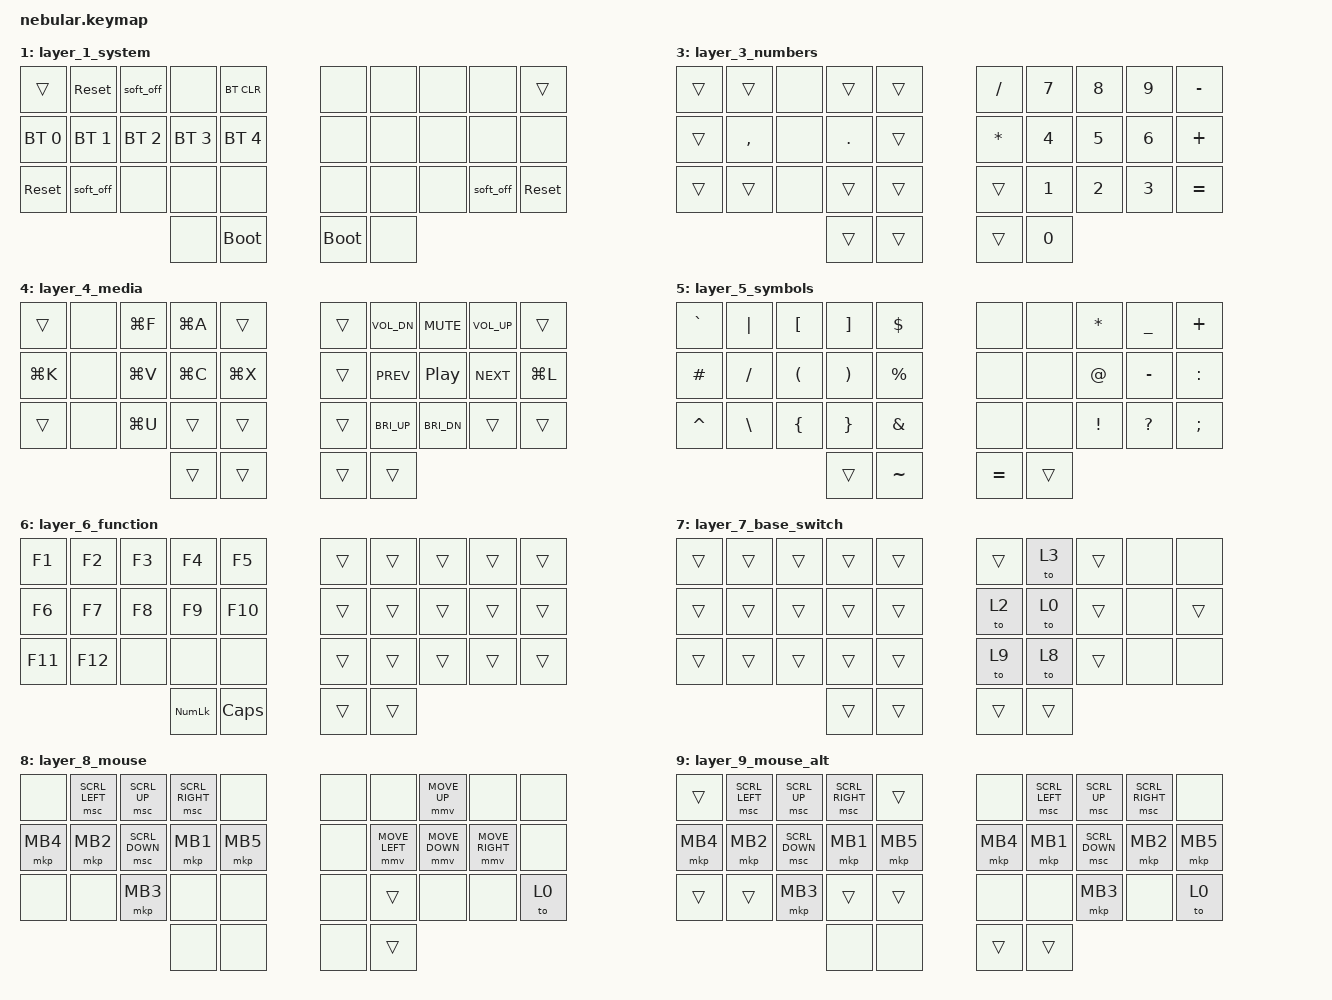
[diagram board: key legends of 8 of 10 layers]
// This file was generated from a template. Edit it to match your keyboard.
// See https://zmk.dev/docs/development/hardware-integration/new-shield for more instructions.
#define ZMK_POINTING_DEFAULT_MOVE_VAL 1500  // default: 600
#define ZMK_POINTING_DEFAULT_SCRL_VAL 20    // default: 10

#include <behaviors.dtsi>
#include <dt-bindings/zmk/keys.h>
#include <dt-bindings/zmk/reset.h>
#include <dt-bindings/zmk/bt.h>
#include <dt-bindings/zmk/outputs.h>
#include <dt-bindings/zmk/mouse.h>
#include <dt-bindings/zmk/pointing.h>


/ {
    behaviors {
        lt: layer_tap {
            compatible = "zmk,behavior-hold-tap";
            #binding-cells = <2>;
            tapping-term-ms = <170>; // tuned value
            quick-tap-ms = <0>;
            flavor = "tap-preferred";
            bindings = <&mo>, <&kp>;
        };

        mtc: mod_tap_custom {
            compatible = "zmk,behavior-hold-tap";
            #binding-cells = <2>;
            tapping-term-ms = <170>; // tuned value
            quick-tap-ms = <0>;
            flavor = "tap-preferred";
            bindings = <&kp>, <&kp>; // Placeholders
        };

        mts: mod_tap_shift_custom {
            compatible = "zmk,behavior-hold-tap";
            #binding-cells = <2>;
            tapping-term-ms = <170>; // tuned value
            quick-tap-ms = <0>;
            flavor = "tap-preferred";
            bindings = <&kp>, <&kp>; // Placeholders
        };
    };

    keymap {
        compatible = "zmk,keymap";

        /* ----- default_layer (Layer 0) -----
         * +---------+---------+---------+---------+---------+   +---------+---------+---------+---------+---------+
         * |  L1_Q   |  LC_W   |  LA_F   |    P    |    B    |   |    J    |  L5_L   |  RA_U   |  RC_Y   |  L1_'   |
         * +---------+---------+---------+---------+---------+   +---------+---------+---------+---------+---------+
         * |  LS_A   |  L4_R   |  L3_S   |  L2_T   |    G    |   |    M    |  L5_N   |  L6_E   |  L7_I   |  RS_O   |
         * +---------+---------+---------+---------+---------+   +---------+---------+---------+---------+---------+
         * |  HYP_Z  |    X    |    C    |    D    |    V    |   |    K    |    H    |    ,    |    .    |    ;    |
         * +---------+---------+---------+---------+---------+   +---------+---------+---------+---------+---------+
         *                               +---------+---------+   +---------+---------+
         *                               | LG_TAB  |   SPC   |   |  BSPC   |  RG_RET |
         *                               +---------+---------+   +---------+---------+
         *                                         +---------+
         *                                         | ENCODER |
         *                                         +---------+
         */
        default_layer {
            bindings = <
                &lt 1 Q                &mtc LCTRL W &mt LALT F    &kp P          &kp B        &kp J    &lt 5 L      &mt RALT U &mt RCTRL Y &lt 1 SQT
                &mts LSHFT A            &lt 4 R     &lt 3 S       &lt 2 T        &kp G        &kp M    &lt 5 N      &lt 6 E      &lt 7 I      &mts RSHFT O
                &mtc LC(LA(LS(LGUI))) Z &kp X       &kp C         &kp D          &kp V        &kp K    &kp H        &kp COMMA  &kp DOT     &kp SEMI
                                                    &mtc LGUI TAB &lt 9 SPACE    &kp BSPC     &mtc RGUI RET
                                                    &mkp LCLK
            >;
        };

        /* ----- layer_1_system (Layer 1) -----
         * +---------+---------+---------+---------+---------+   +---------+---------+---------+---------+---------+
         * |  TRNS   |  RESET  |  S_OFF  | _______ | BT_CLR  |   | _______ | _______ | _______ | _______ |  TRNS   |
         * +---------+---------+---------+---------+---------+   +---------+---------+---------+---------+---------+
         * |  BT_0   |  BT_1   |  BT_2   |  BT_3   |  BT_4   |   | _______ | _______ | _______ | _______ | _______ |
         * +---------+---------+---------+---------+---------+   +---------+---------+---------+---------+---------+
         * |  RESET  |  S_OFF  | _______ | _______ | _______ |   | _______ | _______ | _______ |  S_OFF  |  RESET  |
         * +---------+---------+---------+---------+---------+   +---------+---------+---------+---------+---------+
         *                               +---------+---------+   +---------+---------+
         *                               | _______ |  BOOT   |   |  BOOT   | _______ |
         *                               +---------+---------+   +---------+---------+
         */
        layer_1_system {
            bindings = <
                &trans       &sys_reset   &soft_off    &none        &bt BT_CLR    &none    &none    &none    &none     &trans
                &bt BT_SEL 0 &bt BT_SEL 1 &bt BT_SEL 2 &bt BT_SEL 3 &bt BT_SEL 4  &none    &none    &none    &none     &none
                &sys_reset   &soft_off    &none        &none        &none         &none    &none    &none    &soft_off &sys_reset
                                          &none       &bootloader                 &bootloader &none
            >;
        };

        /* ----- layer_2_navigation (Layer 2) -----
         * +---------+---------+---------+---------+---------+   +---------+---------+---------+---------+---------+
         * | _______ | _______ | _______ | _______ | _______ |   | _______ |  PGUP   |   UP    |  HOME   | _______ |
         * +---------+---------+---------+---------+---------+   +---------+---------+---------+---------+---------+
         * | _______ | _______ | _______ |  TRNS   | _______ |   |  CAPSW  |  LEFT   |  DOWN   |  RGHT   | _______ |
         * +---------+---------+---------+---------+---------+   +---------+---------+---------+---------+---------+
         * | _______ | _______ | _______ | _______ | _______ |   | _______ |  PGDN   |  LGSX   |   END   | _______ |
         * +---------+---------+---------+---------+---------+   +---------+---------+---------+---------+---------+
         *                               +---------+---------+   +---------+---------+
         *                               | _______ |   ESC   |   |   DEL   |  TRNS   |
         *                               +---------+---------+   +---------+---------+
         */
        layer_2_navigation {
            // Note: LGSX = LG(LS(X)) -> Cmd+Shift+X
            bindings = <
                &none       &none                  &none       &none      &none        &kp PG_DN         &kp PG_UP    &kp UP        &kp HOME     &kp END
                &none       &kp LC(LA(LS(LG(T))))  &kp LG(K)   &trans     &none        &kp LG(LS(LBKT))  &kp LEFT     &kp DOWN      &kp RIGHT    &kp LG(LS(RBKT))
                &none       &none                  &none       &none      &none        &caps_word        &kp LG(LBKT)) &kp LG(LS(X)) &kp LG(RBKT)) &none
                                                   &none       &kp ESC                 &kp DEL     &trans
            >;
        };

        /* ----- layer_3_numbers (Layer 3) -----
         * +---------+---------+---------+---------+---------+   +---------+---------+---------+---------+---------+
         * |  TRNS   |  TRNS   | _______ |  TRNS   |  TRNS   |   |    /    |   N7    |   N8    |   N9    |    -    |
         * +---------+---------+---------+---------+---------+   +---------+---------+---------+---------+---------+
         * |  TRNS   |    ,    | _______ |    .    |  TRNS   |   |    *    |   N4    |   N5    |   N6    |    +    |
         * +---------+---------+---------+---------+---------+   +---------+---------+---------+---------+---------+
         * |  TRNS   |  TRNS   | _______ |  TRNS   |  TRNS   |   |  TRNS   |   N1    |   N2    |   N3    |    =    |
         * +---------+---------+---------+---------+---------+   +---------+---------+---------+---------+---------+
         *                               +---------+---------+   +---------+---------+
         *                               |  TRNS   |  TRNS   |   |  TRNS   |   N0    |
         *                               +---------+---------+   +---------+---------+
         */
        layer_3_numbers {
            bindings = <
                &trans     &trans    &none     &trans    &trans       &kp SLASH  &kp N7     &kp N8    &kp N9    &kp MINUS
                &trans     &kp COMMA &none     &kp DOT   &trans       &kp STAR   &kp N4     &kp N5    &kp N6    &kp PLUS
                &trans     &trans    &none     &trans    &trans       &trans     &kp N1     &kp N2    &kp N3    &kp EQUAL
                                               &trans    &trans       &trans     &kp N0
            >;
        };

        /* ----- layer_4_media (Layer 4) -----
         * +---------+---------+---------+---------+---------+   +---------+---------+---------+---------+---------+
         * |  TRNS   | _______ |  FIND   |  SELA   |  TRNS   |   |  TRNS   |  VOL-   |  MUTE   |  VOL+   |  TRNS   |
         * +---------+---------+---------+---------+---------+   +---------+---------+---------+---------+---------+
         * |  LNK?   | _______ |  PASTE  |  COPY   |   CUT   |   |  TRNS   |  PREV   |  PLAY   |  NEXT   |   LOC   |
         * +---------+---------+---------+---------+---------+   +---------+---------+---------+---------+---------+
         * |  TRNS   | _______ |  SRCE?  |  TRNS   |  TRNS   |   |  TRNS   |  BRI+   |  BRI-   |  TRNS   |  TRNS   |
         * +---------+---------+---------+---------+---------+   +---------+---------+---------+---------+---------+
         *                               +---------+---------+   +---------+---------+
         *                               |  TRNS   |  TRNS   |   |  TRNS   |  TRNS   |
         *                               +---------+---------+   +---------+---------+
         */
        layer_4_media {
            // Note: FIND=LG(F), SELA=LG(A), LNK?=LG(K), PASTE=LG(V), COPY=LG(C),
            //       CUT=LG(X), SRCE?=LG(U), LOC=LG(L)
            bindings = <
                &trans      &none      &kp LG(F)  &kp LG(A)  &trans       &trans     &kp C_VOL_DN &kp C_MUTE &kp C_VOL_UP &trans
                &kp LG(K)   &none      &kp LG(V)  &kp LG(C)  &kp LG(X)    &trans     &kp C_PREV   &kp C_PP   &kp C_NEXT   &kp LG(L)
                &trans      &none      &kp LG(U)  &trans     &trans       &trans     &kp C_BRI_UP &kp C_BRI_DN &trans     &trans
                                                  &trans     &trans       &trans     &trans
            >;
        };

        /* ----- layer_5_symbols (Layer 5) -----
         * +---------+---------+---------+---------+---------+   +---------+---------+---------+---------+---------+
         * |    `    |    |    |    [    |    ]    |    $    |   | _______ | _______ |    *    |    _    |    +    |
         * +---------+---------+---------+---------+---------+   +---------+---------+---------+---------+---------+
         * |    #    |    /    |    (    |    )    |    %    |   | _______ | _______ |    @    |    -    |    :    |
         * +---------+---------+---------+---------+---------+   +---------+---------+---------+---------+---------+
         * |    ^    |    \    |    {    |    }    |    &    |   | _______ | _______ |    !    |    ?    |    ;    |
         * +---------+---------+---------+---------+---------+   +---------+---------+---------+---------+---------+
         *                               +---------+---------+   +---------+---------+
         *                               |  TRNS   |    ~    |   |    =    |  TRNS   |
         *                               +---------+---------+   +---------+---------+
         */
        layer_5_symbols {
            bindings = <
                &kp GRAVE   &kp PIPE   &kp LBKT   &kp RBKT   &kp DLLR      &none     &none      &kp ASTRK  &kp UNDER  &kp PLUS
                &kp HASH    &kp FSLH   &kp LPAR   &kp RPAR   &kp PRCNT     &none     &none      &kp AT     &kp MINUS  &kp COLON
                &kp CARET   &kp BSLH   &kp LBRC   &kp RBRC   &kp AMPS      &none     &none      &kp EXCL   &kp QMARK  &kp SEMI
                                                  &trans     &kp TILDE     &kp EQUAL &trans
            >;
        };

        /* ----- layer_6_function (Layer 6) -----
         * +---------+---------+---------+---------+---------+   +---------+---------+---------+---------+---------+
         * |   F1    |   F2    |   F3    |   F4    |   F5    |   |  TRNS   |  TRNS   |  TRNS   |  TRNS   |  TRNS   |
         * +---------+---------+---------+---------+---------+   +---------+---------+---------+---------+---------+
         * |   F6    |   F7    |   F8    |   F9    |   F10   |   |  TRNS   |  TRNS   |  TRNS   |  TRNS   |  TRNS   |
         * +---------+---------+---------+---------+---------+   +---------+---------+---------+---------+---------+
         * |   F11   |   F12   | _______ | _______ | _______ |   |  TRNS   |  TRNS   |  TRNS   |  TRNS   |  TRNS   |
         * +---------+---------+---------+---------+---------+   +---------+---------+---------+---------+---------+
         *                               +---------+---------+   +---------+---------+
         *                               |   NUM   |  CAPS   |   |  TRNS   |  TRNS   |
         *                               +---------+---------+   +---------+---------+
         */
        layer_6_function {
             bindings = <
                &kp F1      &kp F2    &kp F3         &kp F4     &kp F5            &trans &trans &trans &trans &trans
                &kp F6      &kp F7    &kp F8         &kp F9     &kp F10           &trans &trans &trans &trans &trans
                &kp F11     &kp F12   &none          &none      &none             &trans &trans &trans &trans &trans
                                                     &kp KP_NUM &kp CAPS          &trans &trans
             >;
         };

        /* ----- layer_7_base_switch (Layer 7) -----
         * +---------+---------+---------+---------+---------+   +---------+---------+---------+---------+---------+
         * |  TRNS   |  TRNS   |  TRNS   |  TRNS   |  TRNS   |   |  TRNS   |  TO_3   |  TRNS   | _______ | _______ |
         * +---------+---------+---------+---------+---------+   +---------+---------+---------+---------+---------+
         * |  TRNS   |  TRNS   |  TRNS   |  TRNS   |  TRNS   |   |  TO_2   |  TO_0   |  TRNS   | _______ |  TRNS   |
         * +---------+---------+---------+---------+---------+   +---------+---------+---------+---------+---------+
         * |  TRNS   |  TRNS   |  TRNS   |  TRNS   |  TRNS   |   |  TO_9   |  TO_8   |  TRNS   | _______ | _______ |
         * +---------+---------+---------+---------+---------+   +---------+---------+---------+---------+---------+
         *                               +---------+---------+   +---------+---------+
         *                               |  TRNS   |  TRNS   |   |  TRNS   |  TRNS   |
         *                               +---------+---------+   +---------+---------+
         */
        layer_7_base_switch {
            // Note: TO_x switches the base layer permanently. TO_8/TO_9 mapped to none as layers don't exist.
            bindings = <
                &trans      &trans    &trans    &trans    &trans       &trans    &to 3     &trans    &none     &none
                &trans      &trans    &trans    &trans    &trans       &to 2     &to 0     &trans    &none     &trans
                &trans      &trans    &trans    &trans    &trans       &to 9     &to 8     &trans    &none     &none  // Map TO_9 and TO_8 to none
                                      &trans    &trans                 &trans    &trans
            >;
        };

        /* ----- layer_8_mouse (Layer 8) -----
         * +---------+---------+---------+---------+---------+   +---------+---------+---------+---------+---------+
         * | _______ |  SCR_L  |  SCR_U  |  SCR_R  | _______ |   | _______ | _______ |  MOV_U  | _______ | _______ |
         * +---------+---------+---------+---------+---------+   +---------+---------+---------+---------+---------+
         * |  BTN4   |  BTN2   |  SCR_D  |  BTN1   |  BTN5   |   | _______ |  MOV_L  |  MOV_D  |  MOV_R  | _______ |
         * +---------+---------+---------+---------+---------+   +---------+---------+---------+---------+---------+
         * | _______ | _______ |  BTN3   | _______ | _______ |   | _______ |  TRNS   | _______ | _______ |  TO_0   |
         * +---------+---------+---------+---------+---------+   +---------+---------+---------+---------+---------+
         *                               +---------+---------+   +---------+---------+
         *                               | _______ | _______ |   | _______ |  TRNS   |
         *                               +---------+---------+   +---------+---------+
         */
         layer_8_mouse {
             // Note: SCR = Mouse Scroll, MOV = Mouse Move, BTN = Mouse Button
             bindings = <
                &none       &msc SCRL_LEFT  &msc SCRL_UP    &msc SCRL_RIGHT &none        &none  &none           &mmv MOVE_UP    &none           &none
                &mkp MB4    &mkp MB2        &msc SCRL_DOWN  &mkp MB1        &mkp MB5     &none  &mmv MOVE_LEFT  &mmv MOVE_DOWN  &mmv MOVE_RIGHT &none
                &none       &none           &mkp MB3        &none           &none        &none  &trans          &none           &none           &to 0
                                            &none           &none                        &none  &trans
             >;
         };

        /* ----- layer_9_mouse_alt (Layer 9) -----
         * +---------+---------+---------+---------+---------+   +---------+---------+---------+---------+---------+
         * |  TRNS   |  SCR_L  |  SCR_U  |  SCR_R  |  TRNS   |   | _______ |  SCR_L  |  SCR_U  |  SCR_R  | _______ |
         * +---------+---------+---------+---------+---------+   +---------+---------+---------+---------+---------+
         * |  BTN4   |  BTN2   |  SCR_D  |  BTN1   |  BTN5   |   |  BTN4   |  BTN1   |  SCR_D  |  BTN2   |  BTN5   |
         * +---------+---------+---------+---------+---------+   +---------+---------+---------+---------+---------+
         * |  TRNS   |  TRNS   |  BTN3   |  TRNS   |  TRNS   |   | _______ | _______ |  BTN3   | _______ |  TO_0   |
         * +---------+---------+---------+---------+---------+   +---------+---------+---------+---------+---------+
         *                               +---------+---------+   +---------+---------+
         *                               | _______ | _______ |   |  TRNS   |  TRNS   |
         *                               +---------+---------+   +---------+---------+
         */
         layer_9_mouse_alt {
             // Note: SCR = Mouse Scroll, BTN = Mouse Button
             bindings = <
                &trans      &msc SCRL_LEFT  &msc SCRL_UP    &msc SCRL_RIGHT &trans       &none     &msc SCRL_LEFT  &msc SCRL_UP    &msc SCRL_RIGHT &none
                &mkp MB4    &mkp MB2        &msc SCRL_DOWN  &mkp MB1        &mkp MB5     &mkp MB4  &mkp MB1        &msc SCRL_DOWN  &mkp MB2        &mkp MB5
                &trans      &trans          &mkp MB3        &trans          &trans       &none     &none           &mkp MB3        &none           &to 0
                                            &none           &none                        &trans    &trans
             >;
         };
    };

    sensor-bindings = <
        &inc_dec_kp C_VOL_UP C_VOL_DN
    >;
};
